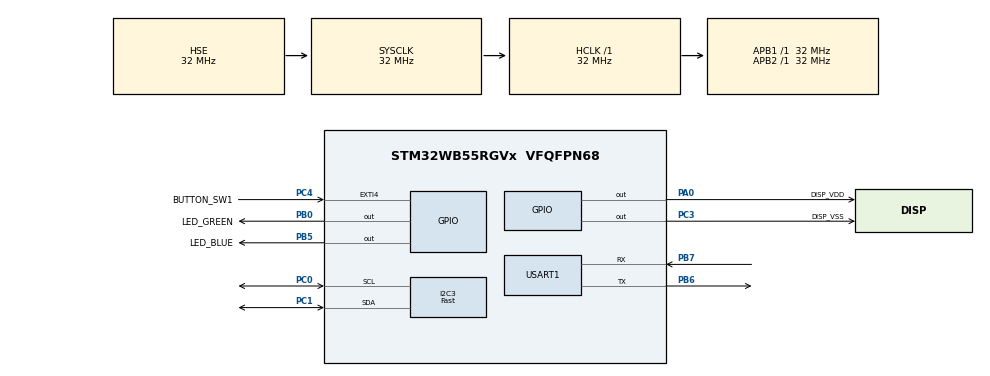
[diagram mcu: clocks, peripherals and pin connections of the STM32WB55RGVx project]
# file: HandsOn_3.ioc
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Dma.Request0=USART1_TX
Dma.USART1_TX.0.Direction=DMA_MEMORY_TO_PERIPH
Dma.USART1_TX.0.EventEnable=DISABLE
Dma.USART1_TX.0.Instance=DMA1_Channel1
Dma.USART1_TX.0.MemDataAlignment=DMA_MDATAALIGN_BYTE
Dma.USART1_TX.0.MemInc=DMA_MINC_ENABLE
Dma.USART1_TX.0.Mode=DMA_NORMAL
Dma.USART1_TX.0.PeriphDataAlignment=DMA_PDATAALIGN_BYTE
Dma.USART1_TX.0.PeriphInc=DMA_PINC_DISABLE
Dma.USART1_TX.0.Polarity=HAL_DMAMUX_REQ_GEN_RISING
Dma.USART1_TX.0.Priority=DMA_PRIORITY_LOW
Dma.USART1_TX.0.RequestNumber=1
Dma.USART1_TX.0.SignalID=NONE
Dma.USART1_TX.0.SyncEnable=DISABLE
Dma.USART1_TX.0.SyncPolarity=HAL_DMAMUX_SYNC_NO_EVENT
Dma.USART1_TX.0.SyncRequestNumber=1
Dma.USART1_TX.0.SyncSignalID=NONE
I2C3.I2C_Fall_Time=100
I2C3.I2C_Rise_Time=100
I2C3.I2C_Speed_Mode=I2C_Fast
I2C3.Timing=0x0060112F
Mcu.Family=STM32WB
Mcu.Name=STM32WB55RGVx
Mcu.Package=VFQFPN68
NVIC.DMA1_Channel1_IRQn=true\:0\:0\:false\:false\:true\:false\:true
NVIC.EXTI4_IRQn=true\:0\:0\:false\:false\:true\:true\:true
NVIC.PriorityGroup=NVIC_PRIORITYGROUP_4
NVIC.USART1_IRQn=true\:0\:0\:false\:false\:true\:true\:true
OSC_IN.Mode=HSE-External-Oscillator
OSC_IN.Signal=RCC_OSC_IN
OSC_OUT.Mode=HSE-External-Oscillator
OSC_OUT.Signal=RCC_OSC_OUT
PA0.GPIO_Label=DISP_VDD
PA0.GPIO_Speed=GPIO_SPEED_FREQ_VERY_HIGH
PA0.PinState=GPIO_PIN_SET
PA0.Signal=GPIO_Output
PA13.Mode=Serial_Wire
PA13.Signal=SYS_JTMS-SWDIO
PA14.Mode=Serial_Wire
PA14.Signal=SYS_JTCK-SWCLK
PB0.GPIO_Label=LED_GREEN
PB0.Signal=GPIO_Output
PB5.GPIO_Label=LED_BLUE
PB5.Signal=GPIO_Output
PB6.Mode=Asynchronous
PB6.Signal=USART1_TX
PB7.Mode=Asynchronous
PB7.Signal=USART1_RX
PC0.GPIO_Speed=GPIO_SPEED_FREQ_HIGH
PC0.Mode=I2C
PC0.Signal=I2C3_SCL
PC1.GPIO_Speed=GPIO_SPEED_FREQ_HIGH
PC1.Mode=I2C
PC1.Signal=I2C3_SDA
PC14-OSC32_IN.Mode=LSE-External-Oscillator
PC14-OSC32_IN.Signal=RCC_OSC32_IN
PC15-OSC32_OUT.Mode=LSE-External-Oscillator
PC15-OSC32_OUT.Signal=RCC_OSC32_OUT
PC3.GPIO_Label=DISP_VSS
PC3.GPIO_Speed=GPIO_SPEED_FREQ_VERY_HIGH
PC3.Signal=GPIO_Output
PC4.GPIO_Label=BUTTON_SW1
PC4.GPIO_ModeDefaultEXTI=GPIO_MODE_IT_FALLING
PC4.GPIO_PuPd=GPIO_PULLUP
PC4.Signal=GPXTI4
ProjectManager.HeapSize=0x200
ProjectManager.StackSize=0x400
ProjectManager.TargetToolchain=TrueSTUDIO
RCC.ADCFreq_Value=128000000
RCC.AHBFreq_Value=32000000
RCC.APB1Freq_Value=32000000
RCC.APB1TimFreq_Value=32000000
RCC.APB2Freq_Value=32000000
RCC.APB2TimFreq_Value=32000000
RCC.APB3Freq_Value=16000000
RCC.CortexFreq_Value=32000000
RCC.HCLKFreq_Value=32000000
RCC.HSE_VALUE=32000000
RCC.HSI48_VALUE=48000000
RCC.HSI_VALUE=16000000
RCC.MSIClockRange=RCC_MSIRANGE_10
RCC.RFWKPClockSelection=RCC_RFWKPCLKSOURCE_LSE
RCC.RTCClockSelection=RCC_RTCCLKSOURCE_LSE
RCC.SMPSDivider=4
RCC.SYSCLKFreq_VALUE=32000000
RCC.SYSCLKSource=RCC_SYSCLKSOURCE_HSE
RCC.USBFreq_Value=128000000
RCC.VCOOutputFreq_Value=256000000
RF1.Mode=RF1_Activate
RF1.Signal=RF_RF1
STM32_WPAN.CFG_DEBUG_APP_TRACE=1
STM32_WPAN.CFG_DEBUG_BLE_TRACE=1
STM32_WPAN.CFG_FAST_CONN_ADV_INTERVAL_MAX_HEXA=0xa0
STM32_WPAN.CFG_HW_USART1_ENABLED=1
STM32_WPAN.CFG_LP_CONN_ADV_INTERVAL_MAX_HEXA=0xfa0
STM32_WPAN.CUSTOM_P2P_SERVER=Enabled
STM32_WPAN.CUSTOM_TEMPLATE=Disabled
STM32_WPAN.DBG_TRACE_UART_CFG=hw_uart1
STM32_WPAN.LOCAL_NAME=XX-NODE
STM32_WPAN.LOCAL_NAME_FORMATTED=,'X','X','-','N','O','D','E'
USART1.VirtualMode-Asynchronous=VM_ASYNC
USART1.WordLength=WORDLENGTH_8B
VP_HSEM_VS_HSEM.Mode=HSEM_Activate
VP_RTC_VS_RTC_Activate.Mode=RTC_Enabled
VP_RTC_VS_RTC_WakeUp_intern.Mode=WakeUp
VP_STM32_WPAN_VS_BLE_HOST.Mode=STM32_WPAN_Enabled
board=custom

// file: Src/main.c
/* USER CODE BEGIN Header */
/**
  ******************************************************************************
  * @file           : main.c
  * @brief          : Main program body
  ******************************************************************************
  * @attention
  *
  * <h2><center>&copy; Copyright (c) 2019 STMicroelectronics.
  * All rights reserved.</center></h2>
  *
  * This software component is licensed by ST under Ultimate Liberty license
  * SLA0044, the "License"; You may not use this file except in compliance with
  * the License. You may obtain a copy of the License at:
  *                             www.st.com/SLA0044
  *
  ******************************************************************************
  */
/* USER CODE END Header */

#include "main.h"
#include "app_entry.h"

/* USER CODE BEGIN Includes */
#include "scheduler.h"
/* USER CODE END Includes */

I2C_HandleTypeDef hi2c3;

RTC_HandleTypeDef hrtc;

UART_HandleTypeDef huart1;
DMA_HandleTypeDef hdma_usart1_tx;

void SystemClock_Config(void);
static void MX_GPIO_Init(void);
static void MX_DMA_Init(void);
static void MX_I2C3_Init(void);
static void MX_USART1_UART_Init(void);
static void MX_RTC_Init(void);
static void MX_RF_Init(void);

int main(void)
{

  /* MCU Configuration--------------------------------------------------------*/

  /* Reset of all peripherals, Initializes the Flash interface and the Systick. */
  HAL_Init();

  /* Configure the system clock */
  SystemClock_Config();

  /* Initialize all configured peripherals */
  MX_GPIO_Init();
  MX_DMA_Init();
  MX_I2C3_Init();
  MX_USART1_UART_Init();
  MX_RTC_Init();
  MX_RF_Init();
  APPE_Init();

  /* Infinite loop */
  while (1)
  {

    /* USER CODE BEGIN 3 */
	SCH_Run(~0);
  }
  /* USER CODE END 3 */
}

void SystemClock_Config(void)
{
  RCC_OscInitTypeDef RCC_OscInitStruct = {0};
  RCC_ClkInitTypeDef RCC_ClkInitStruct = {0};
  RCC_PeriphCLKInitTypeDef PeriphClkInitStruct = {0};

  /** Configure LSE Drive Capability
  */
  __HAL_RCC_LSEDRIVE_CONFIG(RCC_LSEDRIVE_LOW);
  /** Configure the main internal regulator output voltage
  */
  __HAL_PWR_VOLTAGESCALING_CONFIG(PWR_REGULATOR_VOLTAGE_SCALE1);
  /** Initializes the CPU, AHB and APB busses clocks
  */
  RCC_OscInitStruct.OscillatorType = RCC_OSCILLATORTYPE_HSI|RCC_OSCILLATORTYPE_HSE
                              |RCC_OSCILLATORTYPE_LSE;
  RCC_OscInitStruct.HSEState = RCC_HSE_ON;
  RCC_OscInitStruct.LSEState = RCC_LSE_ON;
  RCC_OscInitStruct.HSIState = RCC_HSI_ON;
  RCC_OscInitStruct.HSICalibrationValue = RCC_HSICALIBRATION_DEFAULT;
  RCC_OscInitStruct.PLL.PLLState = RCC_PLL_NONE;
  if (HAL_RCC_OscConfig(&RCC_OscInitStruct) != HAL_OK)
  {
    Error_Handler();
  }
  /** Configure the SYSCLKSource, HCLK, PCLK1 and PCLK2 clocks dividers
  */
  RCC_ClkInitStruct.ClockType = RCC_CLOCKTYPE_HCLK4|RCC_CLOCKTYPE_HCLK2
                              |RCC_CLOCKTYPE_HCLK|RCC_CLOCKTYPE_SYSCLK
                              |RCC_CLOCKTYPE_PCLK1|RCC_CLOCKTYPE_PCLK2;
  RCC_ClkInitStruct.SYSCLKSource = RCC_SYSCLKSOURCE_HSE;
  RCC_ClkInitStruct.AHBCLKDivider = RCC_SYSCLK_DIV1;
  RCC_ClkInitStruct.APB1CLKDivider = RCC_HCLK_DIV1;
  RCC_ClkInitStruct.APB2CLKDivider = RCC_HCLK_DIV1;
  RCC_ClkInitStruct.AHBCLK2Divider = RCC_SYSCLK_DIV1;
  RCC_ClkInitStruct.AHBCLK4Divider = RCC_SYSCLK_DIV1;

  if (HAL_RCC_ClockConfig(&RCC_ClkInitStruct, FLASH_LATENCY_1) != HAL_OK)
  {
    Error_Handler();
  }
  /** Initializes the peripherals clocks
  */
  PeriphClkInitStruct.PeriphClockSelection = RCC_PERIPHCLK_SMPS|RCC_PERIPHCLK_RFWAKEUP
                              |RCC_PERIPHCLK_RTC|RCC_PERIPHCLK_USART1
                              |RCC_PERIPHCLK_I2C3;
  PeriphClkInitStruct.Usart1ClockSelection = RCC_USART1CLKSOURCE_PCLK2;
  PeriphClkInitStruct.I2c3ClockSelection = RCC_I2C3CLKSOURCE_PCLK1;
  PeriphClkInitStruct.RTCClockSelection = RCC_RTCCLKSOURCE_LSE;
  PeriphClkInitStruct.RFWakeUpClockSelection = RCC_RFWKPCLKSOURCE_LSE;
  PeriphClkInitStruct.SmpsClockSelection = RCC_SMPSCLKSOURCE_HSE;
  PeriphClkInitStruct.SmpsDivSelection = RCC_SMPSCLKDIV_RANGE1;

  if (HAL_RCCEx_PeriphCLKConfig(&PeriphClkInitStruct) != HAL_OK)
  {
    Error_Handler();
  }
}

static void MX_I2C3_Init(void)
{

  hi2c3.Instance = I2C3;
  hi2c3.Init.Timing = 0x0060112F;
  hi2c3.Init.OwnAddress1 = 0;
  hi2c3.Init.AddressingMode = I2C_ADDRESSINGMODE_7BIT;
  hi2c3.Init.DualAddressMode = I2C_DUALADDRESS_DISABLE;
  hi2c3.Init.OwnAddress2 = 0;
  hi2c3.Init.OwnAddress2Masks = I2C_OA2_NOMASK;
  hi2c3.Init.GeneralCallMode = I2C_GENERALCALL_DISABLE;
  hi2c3.Init.NoStretchMode = I2C_NOSTRETCH_DISABLE;
  if (HAL_I2C_Init(&hi2c3) != HAL_OK)
  {
    Error_Handler();
  }
  /** Configure Analogue filter
  */
  if (HAL_I2CEx_ConfigAnalogFilter(&hi2c3, I2C_ANALOGFILTER_ENABLE) != HAL_OK)
  {
    Error_Handler();
  }
  /** Configure Digital filter
  */
  if (HAL_I2CEx_ConfigDigitalFilter(&hi2c3, 0) != HAL_OK)
  {
    Error_Handler();
  }

}

static void MX_RF_Init(void)
{

}

static void MX_RTC_Init(void)
{

  /** Initialize RTC Only
  */
  hrtc.Instance = RTC;
  hrtc.Init.HourFormat = RTC_HOURFORMAT_24;
  hrtc.Init.AsynchPrediv = 127;
  hrtc.Init.SynchPrediv = 255;
  hrtc.Init.OutPut = RTC_OUTPUT_DISABLE;
  hrtc.Init.OutPutRemap = RTC_OUTPUT_REMAP_NONE;
  hrtc.Init.OutPutPolarity = RTC_OUTPUT_POLARITY_HIGH;
  hrtc.Init.OutPutType = RTC_OUTPUT_TYPE_OPENDRAIN;
  if (HAL_RTC_Init(&hrtc) != HAL_OK)
  {
    Error_Handler();
  }
  /** Enable the WakeUp
  */
  if (HAL_RTCEx_SetWakeUpTimer(&hrtc, 0, RTC_WAKEUPCLOCK_RTCCLK_DIV16) != HAL_OK)
  {
    Error_Handler();
  }

}

static void MX_USART1_UART_Init(void)
{

  huart1.Instance = USART1;
  huart1.Init.BaudRate = 115200;
  huart1.Init.WordLength = UART_WORDLENGTH_8B;
  huart1.Init.StopBits = UART_STOPBITS_1;
  huart1.Init.Parity = UART_PARITY_NONE;
  huart1.Init.Mode = UART_MODE_TX_RX;
  huart1.Init.HwFlowCtl = UART_HWCONTROL_NONE;
  huart1.Init.OverSampling = UART_OVERSAMPLING_8;
  huart1.Init.OneBitSampling = UART_ONE_BIT_SAMPLE_DISABLE;
  huart1.Init.ClockPrescaler = UART_PRESCALER_DIV1;
  huart1.AdvancedInit.AdvFeatureInit = UART_ADVFEATURE_NO_INIT;
  if (HAL_UART_Init(&huart1) != HAL_OK)
  {
    Error_Handler();
  }
  if (HAL_UARTEx_SetTxFifoThreshold(&huart1, UART_TXFIFO_THRESHOLD_1_8) != HAL_OK)
  {
    Error_Handler();
  }
  if (HAL_UARTEx_SetRxFifoThreshold(&huart1, UART_RXFIFO_THRESHOLD_1_8) != HAL_OK)
  {
    Error_Handler();
  }
  if (HAL_UARTEx_DisableFifoMode(&huart1) != HAL_OK)
  {
    Error_Handler();
  }

}

static void MX_DMA_Init(void)
{
  /* DMA controller clock enable */
  __HAL_RCC_DMAMUX1_CLK_ENABLE();
  __HAL_RCC_DMA1_CLK_ENABLE();

  /* DMA interrupt init */
  /* DMA1_Channel1_IRQn interrupt configuration */
  HAL_NVIC_SetPriority(DMA1_Channel1_IRQn, 0, 0);
  HAL_NVIC_EnableIRQ(DMA1_Channel1_IRQn);

}

static void MX_GPIO_Init(void)
{
  GPIO_InitTypeDef GPIO_InitStruct = {0};

  /* GPIO Ports Clock Enable */
  __HAL_RCC_GPIOC_CLK_ENABLE();
  __HAL_RCC_GPIOA_CLK_ENABLE();
  __HAL_RCC_GPIOB_CLK_ENABLE();

  /*Configure GPIO pin Output Level */
  HAL_GPIO_WritePin(DISP_VSS_GPIO_Port, DISP_VSS_Pin, GPIO_PIN_RESET);

  /*Configure GPIO pin Output Level */
  HAL_GPIO_WritePin(DISP_VDD_GPIO_Port, DISP_VDD_Pin, GPIO_PIN_SET);

  /*Configure GPIO pin Output Level */
  HAL_GPIO_WritePin(GPIOB, LED_GREEN_Pin|LED_BLUE_Pin, GPIO_PIN_RESET);

  /*Configure GPIO pin : DISP_VSS_Pin */
  GPIO_InitStruct.Pin = DISP_VSS_Pin;
  GPIO_InitStruct.Mode = GPIO_MODE_OUTPUT_PP;
  GPIO_InitStruct.Pull = GPIO_NOPULL;
  GPIO_InitStruct.Speed = GPIO_SPEED_FREQ_VERY_HIGH;
  HAL_GPIO_Init(DISP_VSS_GPIO_Port, &GPIO_InitStruct);

  /*Configure GPIO pin : DISP_VDD_Pin */
  GPIO_InitStruct.Pin = DISP_VDD_Pin;
  GPIO_InitStruct.Mode = GPIO_MODE_OUTPUT_PP;
  GPIO_InitStruct.Pull = GPIO_NOPULL;
  GPIO_InitStruct.Speed = GPIO_SPEED_FREQ_VERY_HIGH;
  HAL_GPIO_Init(DISP_VDD_GPIO_Port, &GPIO_InitStruct);

  /*Configure GPIO pin : BUTTON_SW1_Pin */
  GPIO_InitStruct.Pin = BUTTON_SW1_Pin;
  GPIO_InitStruct.Mode = GPIO_MODE_IT_FALLING;
  GPIO_InitStruct.Pull = GPIO_PULLUP;
  HAL_GPIO_Init(BUTTON_SW1_GPIO_Port, &GPIO_InitStruct);

  /*Configure GPIO pins : LED_GREEN_Pin LED_BLUE_Pin */
  GPIO_InitStruct.Pin = LED_GREEN_Pin|LED_BLUE_Pin;
  GPIO_InitStruct.Mode = GPIO_MODE_OUTPUT_PP;
  GPIO_InitStruct.Pull = GPIO_NOPULL;
  GPIO_InitStruct.Speed = GPIO_SPEED_FREQ_LOW;
  HAL_GPIO_Init(GPIOB, &GPIO_InitStruct);

  /* EXTI interrupt init*/
  HAL_NVIC_SetPriority(EXTI4_IRQn, 0, 0);
  HAL_NVIC_EnableIRQ(EXTI4_IRQn);

}

void Error_Handler(void)
{
}

/************************ (C) COPYRIGHT STMicroelectronics *****END OF FILE****/
